# STM32H562 register map
File version: 1.7
CPU: CM33 r0p0, little endian, MPU, FPU, 4 interrupt priority bits
Registers are 32-bit, read-write, reset 0x0 unless marked. A register's access mark holds for its fields unless they carry their own. Offsets are from the block's base; [hi:lo] are bit positions.

## FMAC — Filter Math Accelerator
Base 0x40023C00
Same registers: SEC_FMAC 0x50023C00
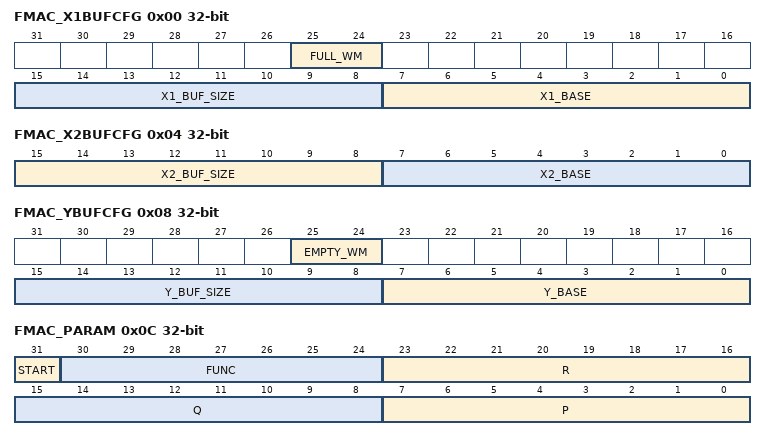
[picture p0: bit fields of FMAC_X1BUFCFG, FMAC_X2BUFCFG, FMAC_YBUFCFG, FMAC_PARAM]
0x00 FMAC_X1BUFCFG — FMAC X1 buffer configuration register
  [25:24] FULL_WM — Watermark for buffer full flag Defines the threshold for setting the X1 buffer full flag when operating in circular mode. The flag is set if the number of free spaces in the buffer is less than 2FULL_WM. 2: Threshold = 4 3: Threshold = 8 Setting a threshold greater than 1 allows several data to be transferred into the buffer under one interrupt. Threshold should be set to 1 if DMA write requests are enabled (DMAWEN = 1 in FMAC_CR register).
    0=Threshold = 1; 1=Threshold = 2
  [15:8] X1_BUF_SIZE — Allocated size of X1 buffer in 16-bit words The minimum buffer size is the number of feed-forward taps in the filter (+ the watermark threshold 1).
  [7:0] X1_BASE — Base address of X1 buffer
0x04 FMAC_X2BUFCFG — FMAC X2 buffer configuration register
  [15:8] X2_BUF_SIZE — Size of X2 buffer in 16-bit words This bitfield can not be modified when a function is ongoing (START = 1).
  [7:0] X2_BASE — Base address of X2 buffer The X2 buffer base address can be modified while START=1, for example to change coefficient values. The filter should be stalled when doing this, since changing the coefficients while a calculation is ongoing affects the result.
0x08 FMAC_YBUFCFG — FMAC Y buffer configuration register
  [25:24] EMPTY_WM — Watermark for buffer empty flag Defines the threshold for setting the Y buffer empty flag when operating in circular mode. The flag is set if the number of unread values in the buffer is less than 2EMPTY_WM. 2: Threshold = 4 3: Threshold = 8 Setting a threshold greater than 1 allows several data to be transferred from the buffer under one interrupt. Threshold should be set to 1 if DMA read requests are enabled (DMAREN = 1 in FMAC_CR register).
    0=Threshold = 1; 1=Threshold = 2
  [15:8] Y_BUF_SIZE — Size of Y buffer in 16-bit words For FIR filters, the minimum buffer size is 1 (+ the watermark threshold). For IIR filters the minimum buffer size is the number of feedback taps (+ the watermark threshold).
  [7:0] Y_BASE — Base address of Y buffer
0x0C FMAC_PARAM — FMAC parameter register
  [31] START — Enable execution Setting this bit triggers the execution of the function selected in the FUNC bitfield. Resetting it by software stops any ongoing function. For initialization functions, this bit is reset by hardware.
    0=Stop execution; 1=Start execution
  [30:24] FUNC — Function 2: Load X2 buffer 3: Load Y buffer 4 to 7: Reserved 8: Convolution (FIR filter) 9: IIR filter (direct form 1) This bitfield can not be modified when a function is ongoing (START = 1)
    1=Load X1 buffer
  [23:16] R — Input parameter R. The value of this parameter is dependent on the function. This bitfield can not be modified when a function is ongoing (START = 1)
  [15:8] Q — Input parameter Q. The value of this parameter is dependent on the function. This bitfield can not be modified when a function is ongoing (START = 1)
  [7:0] P — Input parameter P. The value of this parameter is dependent on the function This bitfield can not be modified when a function is ongoing (START = 1)
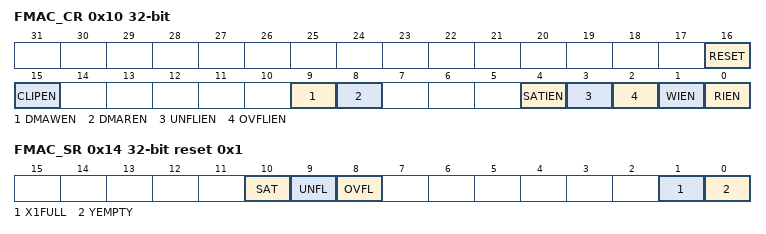
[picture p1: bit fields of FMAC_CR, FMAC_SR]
0x10 FMAC_CR — FMAC control register
  [16] RESET — Reset FMAC unit This resets the write and read pointers, the internal control logic, the FMAC_SR register and the FMAC_PARAM register, including the START bit if active. Other register settings are not affected. This bit is reset by hardware.
    0=Reset inactive; 1=Reset active
  [15] CLIPEN — Enable clipping
    0=Clipping disabled. Values at the output of the accumulator which exceed the q1.15 range, wrap.; 1=Clipping enabled. Values at the output of the accumulator which exceed the q1.15 range are saturated to the maximum positive or negative value (+1 or -1) according to the sign.
  [9] DMAWEN — Enable DMA write channel requests This bit can only be modified when START= 0 in the FMAC_PARAM register. A read returns the current state of the bit.
    0=Disable. No DMA requests are generated; 1=Enable. DMA requests are generated while the X1 buffer is not full.
  [8] DMAREN — Enable DMA read channel requests This bit can only be modified when START= 0 in the FMAC_PARAM register. A read returns the current state of the bit.
    0=Disable. No DMA requests are generated; 1=Enable. DMA requests are generated while the Y buffer is not empty.
  [4] SATIEN — Enable saturation error interrupts This bit is set and cleared by software. A read returns the current state of the bit.
    0=Disabled. No interrupts are generated upon saturation detection.; 1=Enabled. An interrupt request is generated if the SAT flag is set
  [3] UNFLIEN — Enable underflow error interrupts This bit is set and cleared by software. A read returns the current state of the bit.
    0=Disabled. No interrupts are generated upon underflow detection.; 1=Enabled. An interrupt request is generated if the UNFL flag is set
  [2] OVFLIEN — Enable overflow error interrupts This bit is set and cleared by software. A read returns the current state of the bit.
    0=Disabled. No interrupts are generated upon overflow detection.; 1=Enabled. An interrupt request is generated if the OVFL flag is set
  [1] WIEN — Enable write interrupt This bit is set and cleared by software. A read returns the current state of the bit.
    0=Disabled. No write interrupt requests are generated.; 1=Enabled. An interrupt request is generated while the X1 buffer FULL flag is not set.
  [0] RIEN — Enable read interrupt This bit is set and cleared by software. A read returns the current state of the bit.
    0=Disabled. No read interrupt requests are generated.; 1=Enabled. An interrupt request is generated while the Y buffer EMPTY flag is not set.
0x14 FMAC_SR ro reset 0x1 — FMAC status register
  [10] SAT — Saturation error flag Saturation occurs when the result of an accumulation exceeds the numeric range of the accumulator. This flag is cleared by a reset of the unit.
    0=No saturation detected; 1=Saturation detected. If the SATIEN bit is set, an interrupt is generated.
  [9] UNFL — Underflow error flag An underflow occurs when a read is made from FMAC_RDATA when no valid data is available in the Y buffer. This flag is cleared by a reset of the unit.
    0=No underflow detected; 1=Underflow detected. If the UNFLIEN bit is set, an interrupt is generated.
  [8] OVFL — Overflow error flag An overflow occurs when a write is made to FMAC_WDATA when no free space is available in the X1 buffer. This flag is cleared by a reset of the unit.
    0=No overflow detected; 1=Overflow detected. If the OVFLIEN bit is set, an interrupt is generated.
  [1] X1FULL — X1 buffer full flag The buffer is flagged as full if the number of available spaces is less than the FULL_WM threshold. The number of available spaces is the difference between the write pointer and the least recent sample currently in use. This flag is set and cleared by hardware, or by a reset. Note: after the last available space in the X1 buffer is filled there is a delay of 3 clock cycles before the X1FULL flag goes high. To avoid any risk of overflow it is recommended to insert a software delay after writing to the X1 buffer before reading the FMAC_SR. Alternatively, a FULL_WM threshold of 2 can be used.
    0=X1 buffer not full. If the WIEN bit is set, the interrupt request is asserted until the flag is set. If DMAWEN is set, DMA write channel requests are generated until the flag is set.; 1=X1 buffer full
  [0] YEMPTY — Y buffer empty flag The buffer is flagged as empty if the number of unread data is less than the EMPTY_WM threshold. The number of unread data is the difference between the read pointer and the current output destination address. This flag is set and cleared by hardware, or by a reset. Note: after the last sample is read from the Y buffer there is a delay of 3 clock cycles before the YEMPTY flag goes high. To avoid any risk of underflow it is recommended to insert a software delay after reading from the Y buffer before reading the FMAC_SR. Alternatively, an EMPTY_WM threshold of 2 can be used.
    0=Y buffer not empty. If the RIEN bit is set, the interrupt request is asserted until the flag is set. If DMAREN is set, DMA read channel requests are generated until the flag is set.; 1=Y buffer empty
0x18 FMAC_WDATA wo — FMAC write data register
  [15:0] WDATA — Write data When a write access to this register occurs, the write data are transferred to the address offset indicated by the write pointer. The pointer address is automatically incremented after each write access.
0x1C FMAC_RDATA ro — FMAC read data register
  [15:0] RDATA — Read data When a read access to this register occurs, the read data are the contents of the Y output buffer at the address offset indicated by the READ pointer. The pointer address is automatically incremented after each read access.
